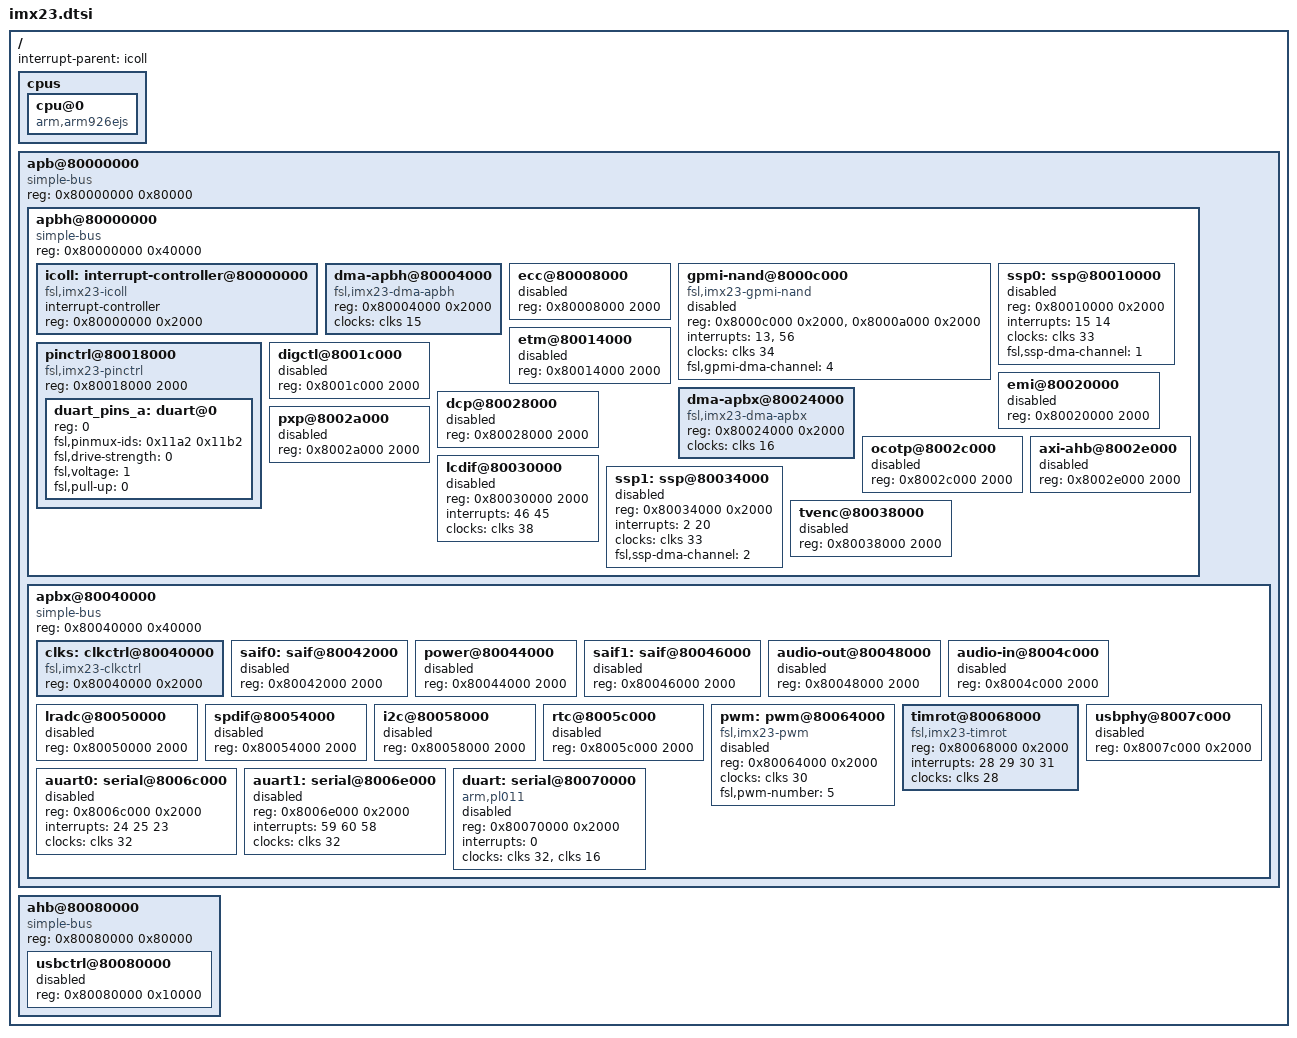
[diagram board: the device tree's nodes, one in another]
/*
 * Copyright 2012 Freescale Semiconductor, Inc.
 *
 * The code contained herein is licensed under the GNU General Public
 * License. You may obtain a copy of the GNU General Public License
 * Version 2 or later at the following locations:
 *
 * http://www.opensource.org/licenses/gpl-license.html
 * http://www.gnu.org/copyleft/gpl.html
 */

/include/ "skeleton.dtsi"

/ {
	interrupt-parent = <&icoll>;

	cpus {
		cpu@0 {
			compatible = "arm,arm926ejs";
		};
	};

	apb@80000000 {
		compatible = "simple-bus";
		#address-cells = <1>;
		#size-cells = <1>;
		reg = <0x80000000 0x80000>;
		ranges;

		apbh@80000000 {
			compatible = "simple-bus";
			#address-cells = <1>;
			#size-cells = <1>;
			reg = <0x80000000 0x40000>;
			ranges;

			icoll: interrupt-controller@80000000 {
				compatible = "fsl,imx23-icoll", "fsl,mxs-icoll";
				interrupt-controller;
				#interrupt-cells = <1>;
				reg = <0x80000000 0x2000>;
			};

			dma-apbh@80004000 {
				compatible = "fsl,imx23-dma-apbh";
				reg = <0x80004000 0x2000>;
				clocks = <&clks 15>;
			};

			ecc@80008000 {
				reg = <0x80008000 2000>;
				status = "disabled";
			};

			gpmi-nand@8000c000 {
				compatible = "fsl,imx23-gpmi-nand";
				#address-cells = <1>;
				#size-cells = <1>;
				reg = <0x8000c000 0x2000>, <0x8000a000 0x2000>;
				reg-names = "gpmi-nand", "bch";
				interrupts = <13>, <56>;
				interrupt-names = "gpmi-dma", "bch";
				clocks = <&clks 34>;
				fsl,gpmi-dma-channel = <4>;
				status = "disabled";
			};

			ssp0: ssp@80010000 {
				reg = <0x80010000 0x2000>;
				interrupts = <15 14>;
				clocks = <&clks 33>;
				fsl,ssp-dma-channel = <1>;
				status = "disabled";
			};

			etm@80014000 {
				reg = <0x80014000 2000>;
				status = "disabled";
			};

			pinctrl@80018000 {
				#address-cells = <1>;
				#size-cells = <0>;
				compatible = "fsl,imx23-pinctrl";
				reg = <0x80018000 2000>;

				duart_pins_a: duart@0 {
					reg = <0>;
					fsl,pinmux-ids = <0x11a2 0x11b2>;
					fsl,drive-strength = <0>;
					fsl,voltage = <1>;
					fsl,pull-up = <0>;
				};
			};

			digctl@8001c000 {
				reg = <0x8001c000 2000>;
				status = "disabled";
			};

			emi@80020000 {
				reg = <0x80020000 2000>;
				status = "disabled";
			};

			dma-apbx@80024000 {
				compatible = "fsl,imx23-dma-apbx";
				reg = <0x80024000 0x2000>;
				clocks = <&clks 16>;
			};

			dcp@80028000 {
				reg = <0x80028000 2000>;
				status = "disabled";
			};

			pxp@8002a000 {
				reg = <0x8002a000 2000>;
				status = "disabled";
			};

			ocotp@8002c000 {
				reg = <0x8002c000 2000>;
				status = "disabled";
			};

			axi-ahb@8002e000 {
				reg = <0x8002e000 2000>;
				status = "disabled";
			};

			lcdif@80030000 {
				reg = <0x80030000 2000>;
				interrupts = <46 45>;
				clocks = <&clks 38>;
				status = "disabled";
			};

			ssp1: ssp@80034000 {
				reg = <0x80034000 0x2000>;
				interrupts = <2 20>;
				clocks = <&clks 33>;
				fsl,ssp-dma-channel = <2>;
				status = "disabled";
			};

			tvenc@80038000 {
				reg = <0x80038000 2000>;
				status = "disabled";
			};
                };

		apbx@80040000 {
			compatible = "simple-bus";
			#address-cells = <1>;
			#size-cells = <1>;
			reg = <0x80040000 0x40000>;
			ranges;

			clks: clkctrl@80040000 {
				compatible = "fsl,imx23-clkctrl";
				reg = <0x80040000 0x2000>;
				#clock-cells = <1>;
			};

			saif0: saif@80042000 {
				reg = <0x80042000 2000>;
				status = "disabled";
			};

			power@80044000 {
				reg = <0x80044000 2000>;
				status = "disabled";
			};

			saif1: saif@80046000 {
				reg = <0x80046000 2000>;
				status = "disabled";
			};

			audio-out@80048000 {
				reg = <0x80048000 2000>;
				status = "disabled";
			};

			audio-in@8004c000 {
				reg = <0x8004c000 2000>;
				status = "disabled";
			};

			lradc@80050000 {
				reg = <0x80050000 2000>;
				status = "disabled";
			};

			spdif@80054000 {
				reg = <0x80054000 2000>;
				status = "disabled";
			};

			i2c@80058000 {
				reg = <0x80058000 2000>;
				status = "disabled";
			};

			rtc@8005c000 {
				reg = <0x8005c000 2000>;
				status = "disabled";
			};

			pwm: pwm@80064000 {
				compatible = "fsl,imx23-pwm";
				reg = <0x80064000 0x2000>;
				clocks = <&clks 30>;
				#pwm-cells = <2>;
				fsl,pwm-number = <5>;
				status = "disabled";
			};

			timrot@80068000 {
				compatible = "fsl,imx23-timrot", "fsl,timrot";
				reg = <0x80068000 0x2000>;
				interrupts = <28 29 30 31>;
				clocks = <&clks 28>;
			};

			auart0: serial@8006c000 {
				reg = <0x8006c000 0x2000>;
				interrupts = <24 25 23>;
				clocks = <&clks 32>;
				status = "disabled";
			};

			auart1: serial@8006e000 {
				reg = <0x8006e000 0x2000>;
				interrupts = <59 60 58>;
				clocks = <&clks 32>;
				status = "disabled";
			};

			duart: serial@80070000 {
				compatible = "arm,pl011", "arm,primecell";
				reg = <0x80070000 0x2000>;
				interrupts = <0>;
				clocks = <&clks 32>, <&clks 16>;
				clock-names = "uart", "apb_pclk";
				status = "disabled";
			};

			usbphy@8007c000 {
				reg = <0x8007c000 0x2000>;
				status = "disabled";
			};
		};
	};

	ahb@80080000 {
		compatible = "simple-bus";
		#address-cells = <1>;
		#size-cells = <1>;
		reg = <0x80080000 0x80000>;
		ranges;

		usbctrl@80080000 {
			reg = <0x80080000 0x10000>;
			status = "disabled";
		};
	};
};
